AUTOSAR XML (schema 00050)
package /Components
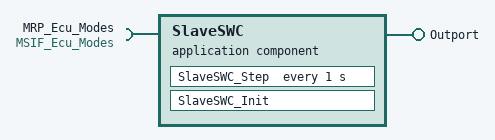
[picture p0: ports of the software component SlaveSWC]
  application sw component type SlaveSWC
    provide port Outport: nonqueued-sender-com-spec{data-element=Outport, init-value=0}, provided-interface=Outport
    require port MRP_Ecu_Modes: required-interface=MSIF_Ecu_Modes
    behavior MasterSWC_IB: data-type-mapping=MasterSWCDataTypeMappingsSet, handle-termination-and-restart=NO-SUPPORT
      timing event SlaveSWC_TE: start-on-event=SlaveSWC_Step, period=1
      runnable SlaveSWC_Step: sw-addr-method=CODE, mode-access-point=MRP_Ecu_Modes.MG_Ecu_Modes
        data-write-access:
          access OUT_Outport_Outport: accessed-variable=Outport.Outport
      runnable SlaveSWC_Init: sw-addr-method=CODE
        data-write-access:
          access OUT_Outport_Outport: accessed-variable=Outport.Outport
